# iostm32f205zx register map
Registers are 32-bit, access not given, no defined reset value unless marked. A register's access mark holds for its fields unless they carry their own. Addresses are absolute; registers are grouped by the start of their names; [hi:lo] are bit positions; {n}, {i} and the like mark numbered series.

## GPIOA
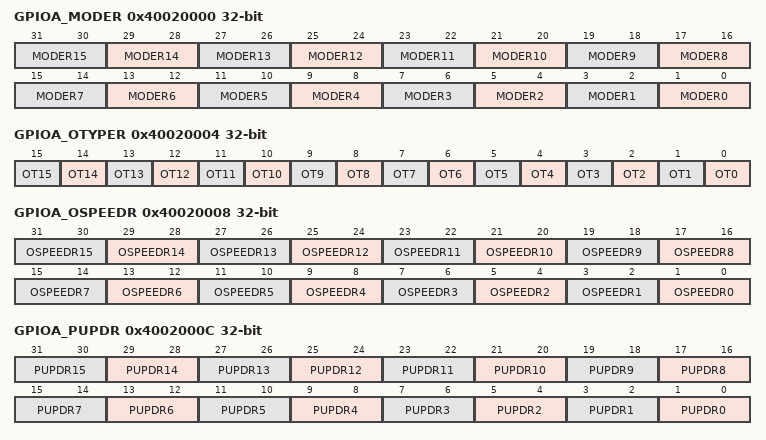
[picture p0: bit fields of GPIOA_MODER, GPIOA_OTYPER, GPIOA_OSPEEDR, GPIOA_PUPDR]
0x40020000 GPIOA_MODER
  [2n+1:2n] MODER{n} (n=0..15)
0x40020004 GPIOA_OTYPER
  [n] OT{n} (n=0..15)
0x40020008 GPIOA_OSPEEDR
  [2n+1:2n] OSPEEDR{n} (n=0..15)
0x4002000C GPIOA_PUPDR
  [2n+1:2n] PUPDR{n} (n=0..15)
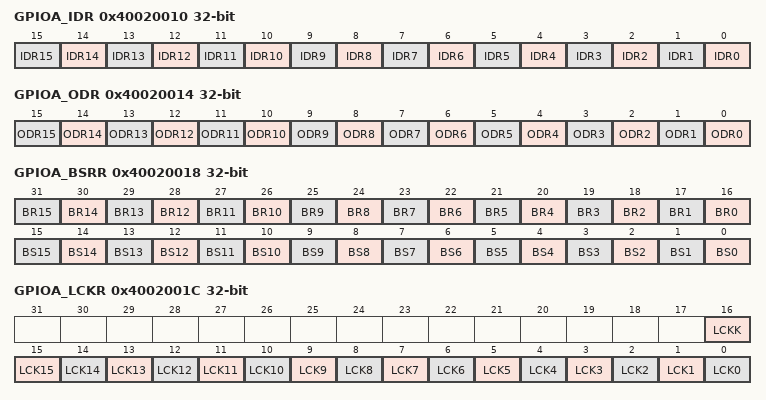
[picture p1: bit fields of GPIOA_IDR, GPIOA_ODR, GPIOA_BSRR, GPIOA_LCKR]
0x40020010 GPIOA_IDR
  [n] IDR{n} (n=0..15)
0x40020014 GPIOA_ODR
  [n] ODR{n} (n=0..15)
0x40020018 GPIOA_BSRR
  [n+16] BR{n} (n=0..15), [n] BS{n} (n=0..15)
0x4002001C GPIOA_LCKR
  [16] LCKK, [n] LCK{n} (n=0..15)
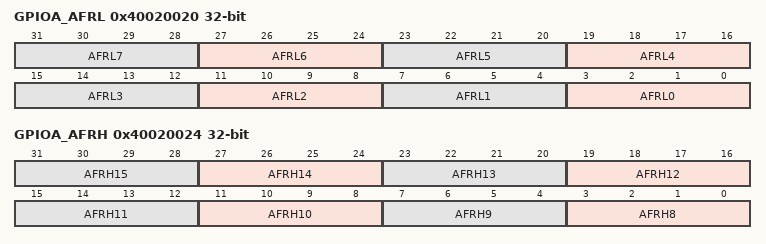
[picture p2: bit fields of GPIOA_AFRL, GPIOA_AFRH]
0x40020020 GPIOA_AFRL
  [4n+3:4n] AFRL{n} (n=0..7)
0x40020024 GPIOA_AFRH
  [4n-29:4n-32] AFRH{n} (n=8..15)

## GPIOB
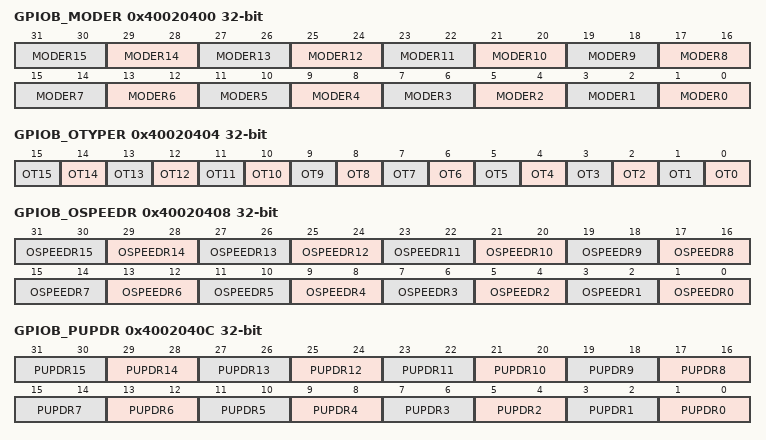
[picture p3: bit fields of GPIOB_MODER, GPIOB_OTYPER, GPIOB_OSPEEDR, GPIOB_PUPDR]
0x40020400 GPIOB_MODER
  [2n+1:2n] MODER{n} (n=0..15)
0x40020404 GPIOB_OTYPER
  [n] OT{n} (n=0..15)
0x40020408 GPIOB_OSPEEDR
  [2n+1:2n] OSPEEDR{n} (n=0..15)
0x4002040C GPIOB_PUPDR
  [2n+1:2n] PUPDR{n} (n=0..15)
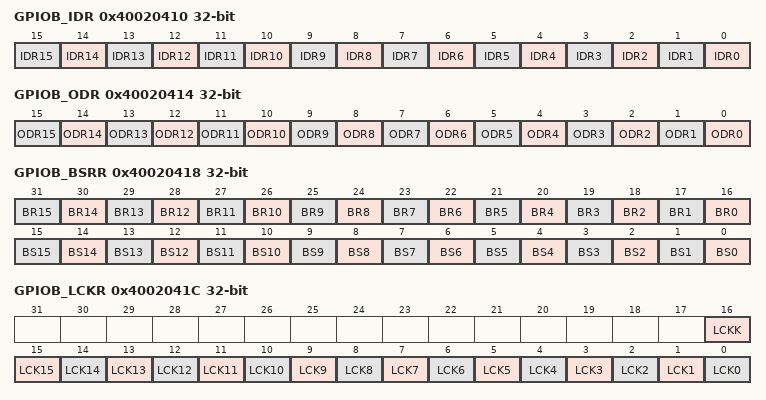
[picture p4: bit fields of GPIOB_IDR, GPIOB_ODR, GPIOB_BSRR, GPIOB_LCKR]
0x40020410 GPIOB_IDR
  [n] IDR{n} (n=0..15)
0x40020414 GPIOB_ODR
  [n] ODR{n} (n=0..15)
0x40020418 GPIOB_BSRR
  [n+16] BR{n} (n=0..15), [n] BS{n} (n=0..15)
0x4002041C GPIOB_LCKR
  [16] LCKK, [n] LCK{n} (n=0..15)
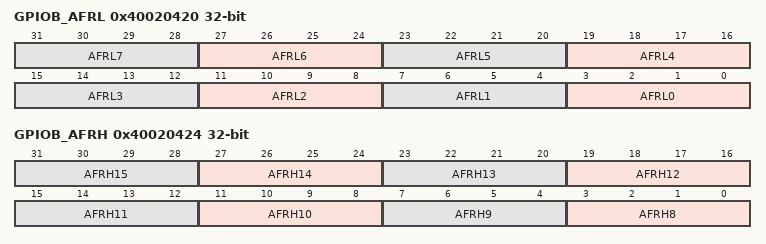
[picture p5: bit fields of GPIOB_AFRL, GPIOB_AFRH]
0x40020420 GPIOB_AFRL
  [4n+3:4n] AFRL{n} (n=0..7)
0x40020424 GPIOB_AFRH
  [4n-29:4n-32] AFRH{n} (n=8..15)

## GPIOC
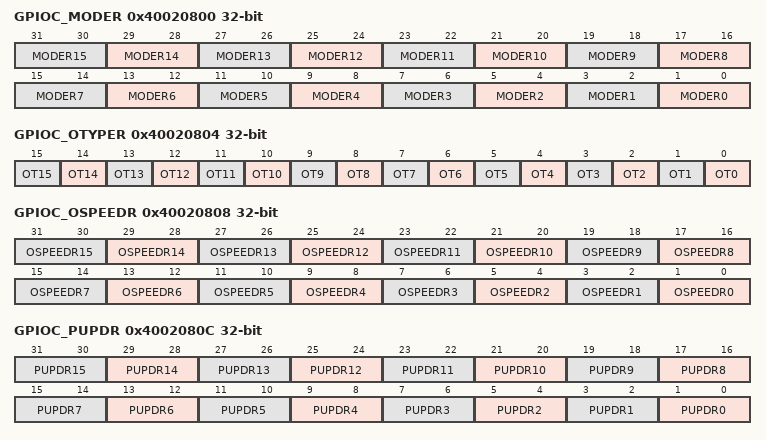
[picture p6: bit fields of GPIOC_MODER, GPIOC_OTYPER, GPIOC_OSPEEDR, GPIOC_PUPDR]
0x40020800 GPIOC_MODER
  [2n+1:2n] MODER{n} (n=0..15)
0x40020804 GPIOC_OTYPER
  [n] OT{n} (n=0..15)
0x40020808 GPIOC_OSPEEDR
  [2n+1:2n] OSPEEDR{n} (n=0..15)
0x4002080C GPIOC_PUPDR
  [2n+1:2n] PUPDR{n} (n=0..15)
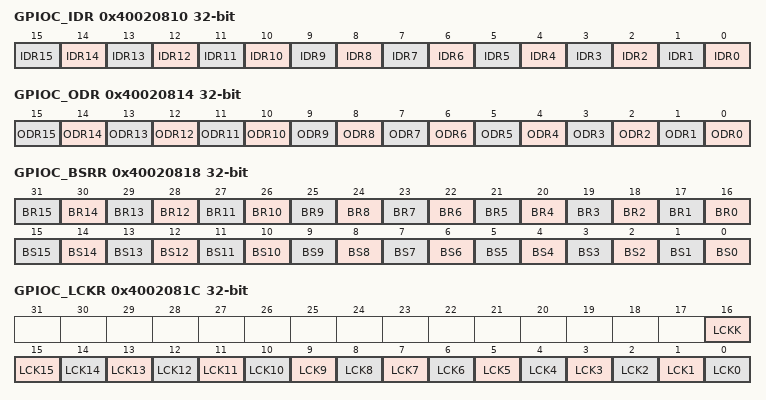
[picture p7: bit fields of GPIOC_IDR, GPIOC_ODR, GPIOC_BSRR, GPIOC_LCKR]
0x40020810 GPIOC_IDR
  [n] IDR{n} (n=0..15)
0x40020814 GPIOC_ODR
  [n] ODR{n} (n=0..15)
0x40020818 GPIOC_BSRR
  [n+16] BR{n} (n=0..15), [n] BS{n} (n=0..15)
0x4002081C GPIOC_LCKR
  [16] LCKK, [n] LCK{n} (n=0..15)
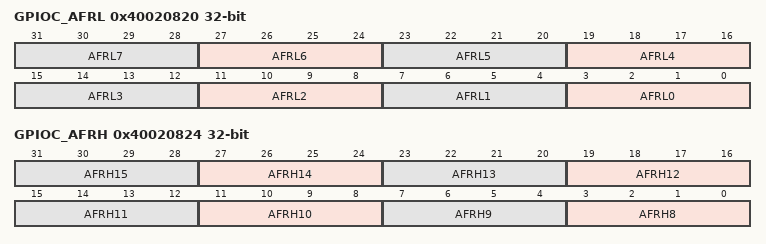
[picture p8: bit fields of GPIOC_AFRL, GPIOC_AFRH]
0x40020820 GPIOC_AFRL
  [4n+3:4n] AFRL{n} (n=0..7)
0x40020824 GPIOC_AFRH
  [4n-29:4n-32] AFRH{n} (n=8..15)

## GPIOD
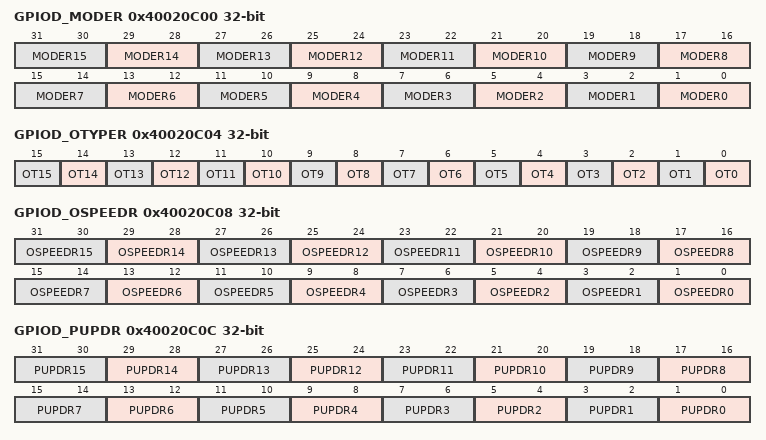
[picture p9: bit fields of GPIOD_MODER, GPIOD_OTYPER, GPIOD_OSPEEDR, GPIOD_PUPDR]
0x40020C00 GPIOD_MODER
  [2n+1:2n] MODER{n} (n=0..15)
0x40020C04 GPIOD_OTYPER
  [n] OT{n} (n=0..15)
0x40020C08 GPIOD_OSPEEDR
  [2n+1:2n] OSPEEDR{n} (n=0..15)
0x40020C0C GPIOD_PUPDR
  [2n+1:2n] PUPDR{n} (n=0..15)
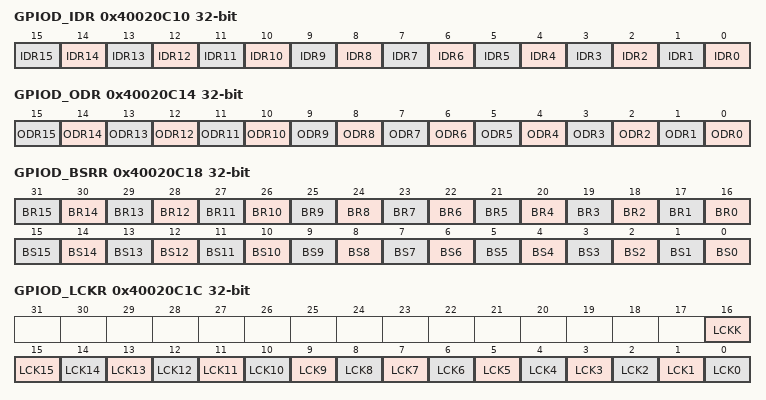
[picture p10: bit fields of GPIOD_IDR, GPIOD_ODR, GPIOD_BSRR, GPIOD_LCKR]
0x40020C10 GPIOD_IDR
  [n] IDR{n} (n=0..15)
0x40020C14 GPIOD_ODR
  [n] ODR{n} (n=0..15)
0x40020C18 GPIOD_BSRR
  [n+16] BR{n} (n=0..15), [n] BS{n} (n=0..15)
0x40020C1C GPIOD_LCKR
  [16] LCKK, [n] LCK{n} (n=0..15)
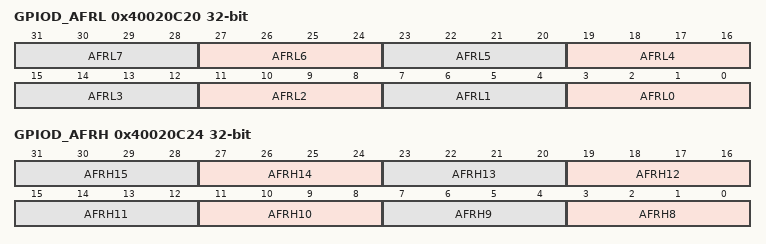
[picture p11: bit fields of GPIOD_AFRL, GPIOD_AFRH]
0x40020C20 GPIOD_AFRL
  [4n+3:4n] AFRL{n} (n=0..7)
0x40020C24 GPIOD_AFRH
  [4n-29:4n-32] AFRH{n} (n=8..15)

## GPIOE
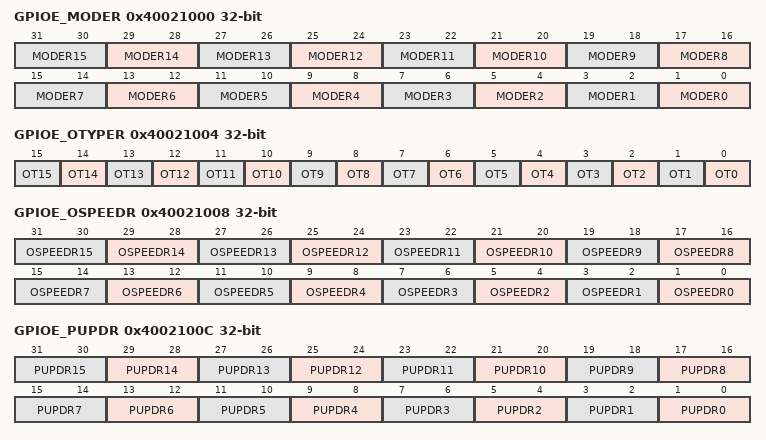
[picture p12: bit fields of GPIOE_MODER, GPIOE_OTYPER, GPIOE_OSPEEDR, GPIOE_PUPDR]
0x40021000 GPIOE_MODER
  [2n+1:2n] MODER{n} (n=0..15)
0x40021004 GPIOE_OTYPER
  [n] OT{n} (n=0..15)
0x40021008 GPIOE_OSPEEDR
  [2n+1:2n] OSPEEDR{n} (n=0..15)
0x4002100C GPIOE_PUPDR
  [2n+1:2n] PUPDR{n} (n=0..15)
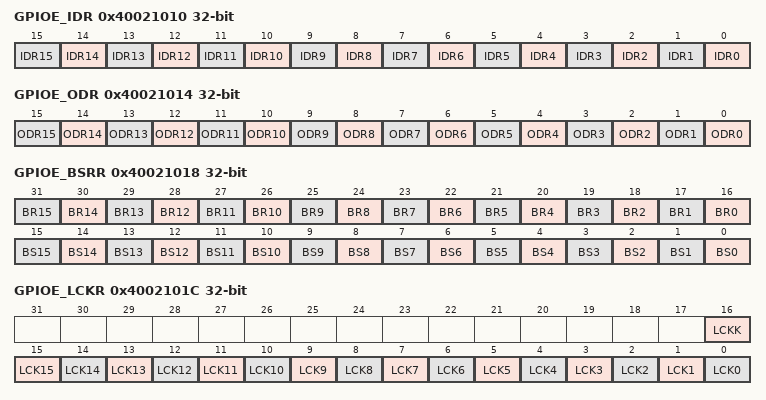
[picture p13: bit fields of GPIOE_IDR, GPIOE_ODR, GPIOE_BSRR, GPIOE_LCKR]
0x40021010 GPIOE_IDR
  [n] IDR{n} (n=0..15)
0x40021014 GPIOE_ODR
  [n] ODR{n} (n=0..15)
0x40021018 GPIOE_BSRR
  [n+16] BR{n} (n=0..15), [n] BS{n} (n=0..15)
0x4002101C GPIOE_LCKR
  [16] LCKK, [n] LCK{n} (n=0..15)
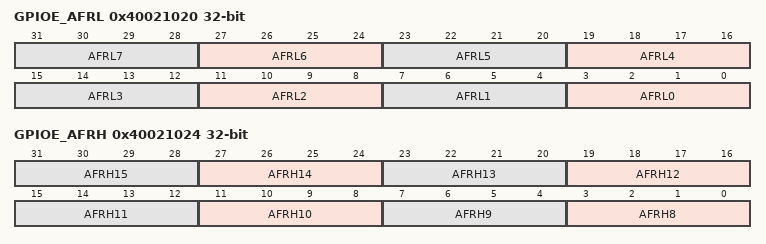
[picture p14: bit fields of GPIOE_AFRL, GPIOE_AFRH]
0x40021020 GPIOE_AFRL
  [4n+3:4n] AFRL{n} (n=0..7)
0x40021024 GPIOE_AFRH
  [4n-29:4n-32] AFRH{n} (n=8..15)

## GPIOF
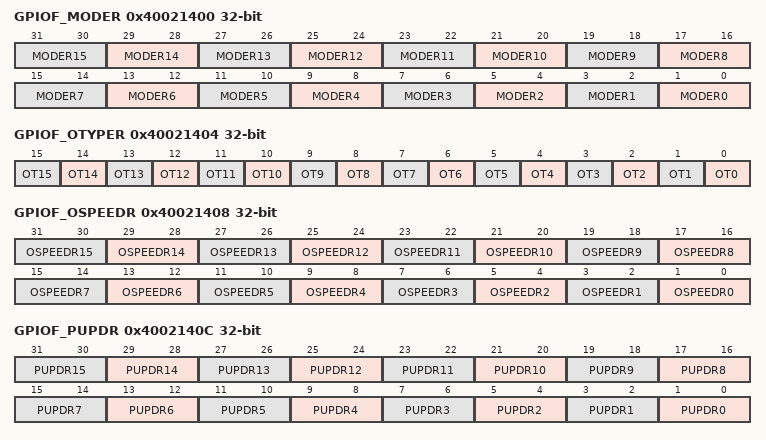
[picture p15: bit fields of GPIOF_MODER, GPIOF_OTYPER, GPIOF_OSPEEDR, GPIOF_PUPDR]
0x40021400 GPIOF_MODER
  [2n+1:2n] MODER{n} (n=0..15)
0x40021404 GPIOF_OTYPER
  [n] OT{n} (n=0..15)
0x40021408 GPIOF_OSPEEDR
  [2n+1:2n] OSPEEDR{n} (n=0..15)
0x4002140C GPIOF_PUPDR
  [2n+1:2n] PUPDR{n} (n=0..15)
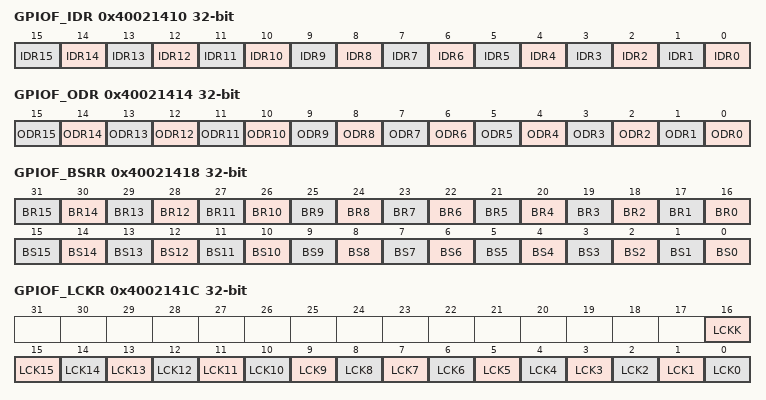
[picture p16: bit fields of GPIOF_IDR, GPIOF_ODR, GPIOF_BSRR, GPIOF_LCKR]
0x40021410 GPIOF_IDR
  [n] IDR{n} (n=0..15)
0x40021414 GPIOF_ODR
  [n] ODR{n} (n=0..15)
0x40021418 GPIOF_BSRR
  [n+16] BR{n} (n=0..15), [n] BS{n} (n=0..15)
0x4002141C GPIOF_LCKR
  [16] LCKK, [n] LCK{n} (n=0..15)
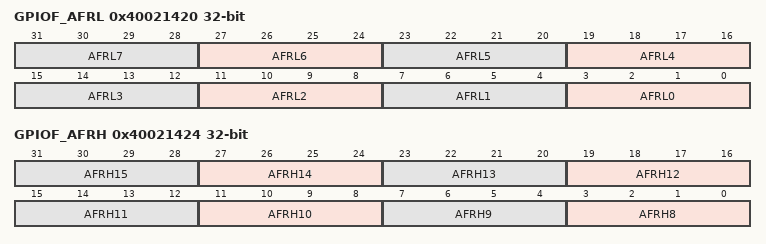
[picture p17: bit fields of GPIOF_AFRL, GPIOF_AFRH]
0x40021420 GPIOF_AFRL
  [4n+3:4n] AFRL{n} (n=0..7)
0x40021424 GPIOF_AFRH
  [4n-29:4n-32] AFRH{n} (n=8..15)

## GPIOG
0x40021800 GPIOG_MODER
  [2n+1:2n] MODER{n} (n=0..15)
0x40021804 GPIOG_OTYPER
  [n] OT{n} (n=0..15)
0x40021808 GPIOG_OSPEEDR
  [2n+1:2n] OSPEEDR{n} (n=0..15)
0x4002180C GPIOG_PUPDR
  [2n+1:2n] PUPDR{n} (n=0..15)
0x40021810 GPIOG_IDR
  [n] IDR{n} (n=0..15)
0x40021814 GPIOG_ODR
  [n] ODR{n} (n=0..15)
0x40021818 GPIOG_BSRR
  [n+16] BR{n} (n=0..15), [n] BS{n} (n=0..15)
0x4002181C GPIOG_LCKR
  [16] LCKK, [n] LCK{n} (n=0..15)
0x40021820 GPIOG_AFRL
  [4n+3:4n] AFRL{n} (n=0..7)
0x40021824 GPIOG_AFRH
  [4n-29:4n-32] AFRH{n} (n=8..15)
